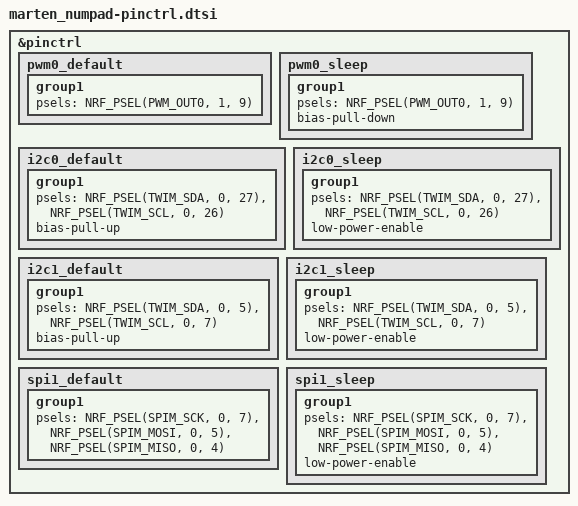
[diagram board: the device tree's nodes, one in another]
#include <dt-bindings/pinctrl/nrf-pinctrl.h>

&pinctrl {
    // PWM LEDs
    pwm0_default: pwm0_default {
        group1 {
            psels = <NRF_PSEL(PWM_OUT0, 1, 9)>;  // Status LED
        };
    };

    pwm0_sleep: pwm0_sleep {
        group1 {
            psels = <NRF_PSEL(PWM_OUT0, 1, 9)>;  // Status LED
            bias-pull-down;
        };
    };

    // I2C for nPM1300
    i2c0_default: i2c0_default {
        group1 {
            psels = <NRF_PSEL(TWIM_SDA, 0, 27)>,
                    <NRF_PSEL(TWIM_SCL, 0, 26)>;
            bias-pull-up;
        };
    };

    i2c0_sleep: i2c0_sleep {
        group1 {
            psels = <NRF_PSEL(TWIM_SDA, 0, 27)>,
                    <NRF_PSEL(TWIM_SCL, 0, 26)>;
            low-power-enable;
        };
    };

    // I2C for peripheral
    i2c1_default: i2c1_default {
        group1 {
            psels = <NRF_PSEL(TWIM_SDA, 0, 5)>,
                    <NRF_PSEL(TWIM_SCL, 0, 7)>;
            bias-pull-up;
        };
    };

    i2c1_sleep: i2c1_sleep {
        group1 {
            psels = <NRF_PSEL(TWIM_SDA, 0, 5)>,
                    <NRF_PSEL(TWIM_SCL, 0, 7)>;
            low-power-enable;
        };
    };

    // SPI for peripheral
    spi1_default: spi1_default {
        group1 {
            psels = <NRF_PSEL(SPIM_SCK, 0, 7)>,
                    <NRF_PSEL(SPIM_MOSI, 0, 5)>,
                    <NRF_PSEL(SPIM_MISO, 0, 4)>;
        };
    };

    spi1_sleep: spi1_sleep {
        group1 {
            psels = <NRF_PSEL(SPIM_SCK, 0, 7)>,
                    <NRF_PSEL(SPIM_MOSI, 0, 5)>,
                    <NRF_PSEL(SPIM_MISO, 0, 4)>;
            low-power-enable;
        };
    };
};
